# K1921VK01T register map
Vendor: NIIET; Series: K1921VKx; File version: 2.2
CPU: CM4 r0p1, little endian, MPU, FPU, 3 interrupt priority bits
Registers are 32-bit, read-write, reset 0x0 unless marked. A register's access mark holds for its fields unless they carry their own. Offsets are from the block's base; [hi:lo] are bit positions.

## NT_USBHost — USB Host controller registers
Base 0x80090000
0x00 VERSION ro — Host controller USB version register
  [7:0] VERSION
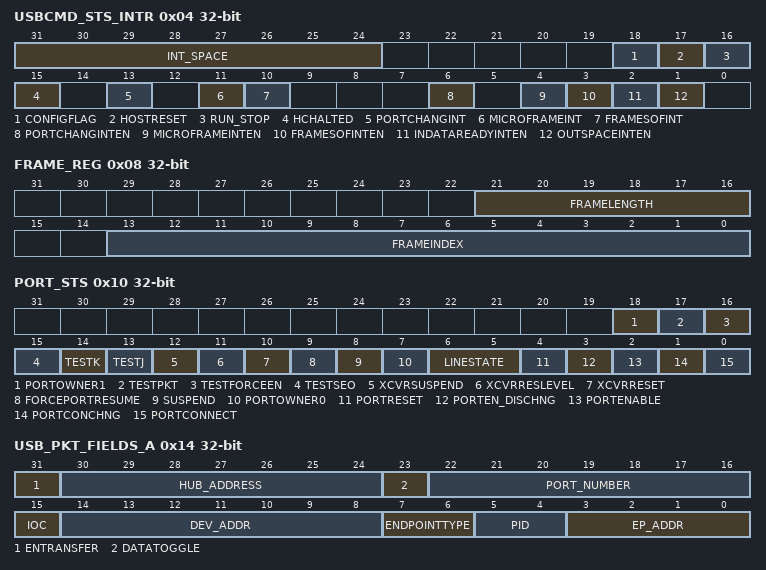
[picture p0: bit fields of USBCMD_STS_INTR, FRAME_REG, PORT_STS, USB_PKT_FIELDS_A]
0x04 USBCMD_STS_INTR — HC Control register 1
  [31:24] INT_SPACE ro
  [18] CONFIGFLAG — Configurate flag
  [17] HOSTRESET — Initial state of USB-controller
  [16] RUN_STOP — Perfoms data
  [15] HCHALTED ro — Indicator controller stop
  [13] PORTCHANGINT — Indicate the any port has a change bit transmission from 0 to 1
  [11] MICROFRAMEINT — Interrupt flag Microframesof
  [10] FRAMESOFINT — Interrupt flag Framesof
  [6] PORTCHANGINTEN wo — Enable interrupt Port change detect
  [4] MICROFRAMEINTEN wo — Enable interrupt Microframe soa
  [3] FRAMESOFINTEN wo — Enable interrupt Frame sof
  [2] INDATAREADYINTEN wo — Enable interrupt InDataReady
  [1] OUTSPACEINTEN ro — Hardware interrupt enable bit
0x08 FRAME_REG — Register version
  [21:16] FRAMELENGTH ro — Micro frame length
  [13:0] FRAMEINDEX — Field of the countdown
0x10 PORT_STS — HC Control register 2
  [18] PORTOWNER1 ro — Indicator low-speed devices
  [17] TESTPKT — Bits select the standard USB
  [16] TESTFORCEEN — Enable transmit packets looped
  [15] TESTSEO — Enable keep in line condition SEO
  [14] TESTK — Enable keep in line condition HS K
  [13] TESTJ — keep in line condition HS J
  [12] XCVRSUSPEND
  [11] XCVRRESLEVEL — Bit setting active level reset signal transceiver
  [10] XCVRRESET — Reset bit transceiver
  [9] FORCEPORTRESUME — Flag resume
  [8] SUSPEND — Bit suspension of work
  [7] PORTOWNER0 ro — Bit with bit PORTOWNER1 assignment of the port speed
  [6:5] LINESTATE ro — Field reflect the current logic level signals D + and D-
  [4] PORTRESET — Setting bit starts the reset procedure in accordance with USB2.0
  [3] PORTEN_DISCHNG — Indicator status change bit PORTENABLE
  [2] PORTENABLE — Enable bit port
  [1] PORTCONCHNG — Indicator status change bit PORTCONNECT
  [0] PORTCONNECT — Indicator device connection
0x14 USB_PKT_FIELDS_A — Transmission Control register A
  [31] ENTRANSFER — Beginning of the current permission bits of data
  [30:24] HUB_ADDRESS
  [23] DATATOGGLE — Identifier field data to be used in the current transmission
  [22:16] PORT_NUMBER
  [15] IOC — Bits specify the behavior of the host controller when transfer
  [14:8] DEV_ADDR
  [7:6] ENDPOINTTYPE — Buffer type
  [5:4] PID
    0=Out; 1=In; 2=Setup; 3=Ping
  [3:0] EP_ADDR
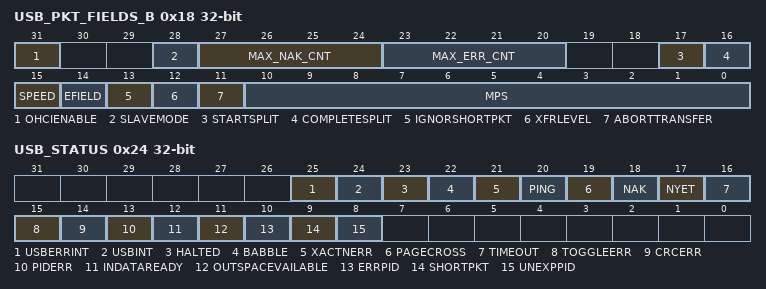
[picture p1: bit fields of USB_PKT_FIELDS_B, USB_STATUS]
0x18 USB_PKT_FIELDS_B — Transmission Control register B
  [31] OHCIENABLE — Demand indicator
  [28] SLAVEMODE — Enable slave mode
  [27:24] MAX_NAK_CNT — Maximum number of labels NAK, which is allowed to accept the host.
  [23:20] MAX_ERR_CNT — Field the maximum number of consecutive transmission errors
  [17] STARTSPLIT — Bit run operations such as Split
  [16] COMPLETESPLIT — Complete bit operations such as Split
  [15] SPEED — Indicator the type of device connected to the router and port
  [14] EFIELD — Bit transmission control
  [13] IGNORSHORTPKT — Enable bit ignore short packets
  [12] XFRLEVEL
  [11] ABORTTRANSFER — Bit the current operation
  [10:0] MPS
0x1C BUFF_START_ADDR — Bufer start address register
  [31:0] BUFFSTARTADDR
0x20 TBT — Transmission data register
  [19:0] TOTALBTRANS — Total Byte transfer
0x24 USB_STATUS ro — XFR STATUS register
  [25] USBERRINT — Error flag that indicates that the last operation was completed due to an erroneous bus state
  [24] USBINT — Flag of the last operation
  [23] HALTED — Flag of finding the system in state Stall or Packet Babble
  [22] BABBLE — Flag of finding the system in state Packet Babble
  [21] XACTNERR
  [20] PING — Flag response
  [19] PAGECROSS — Flag requirements transmission pagecross
  [18] NAK — Receiving flag tags NAK
  [17] NYET — Receiving flag tags NYET
  [16] TIMEOUT — Flag timeout response
  [15] TOGGLEERR — Receiving flag bit wrong DATATOGGLE
  [14] CRCERR — CRC error in receiving data
  [13] PIDERR — Receiving flag incorrect PID
  [12] INDATAREADY — Flag successful completion of an inbound operation
  [11] OUTSPACEVAILABLE — Request flag outbound operation with an empty data buffer
  [10] ERRPID — Flag to receive a response to the label ERROR PID Complete Split
  [9] SHORTPKT — Flag receiving fewer bits than indicated in the register TOTAL_BYTES_TRANS TBT
  [8] UNEXPPID — Receiving flag PID, different from the expected
0x2C Data_Buffer
  [31:0] DATA — Data Buffer
0x30 SLAVE_IN_COUNT ro — Register received data
  [10:0] BYTECOUNT — Indication of the number of bytes received from the device when prompted interruption 'Data ready'
